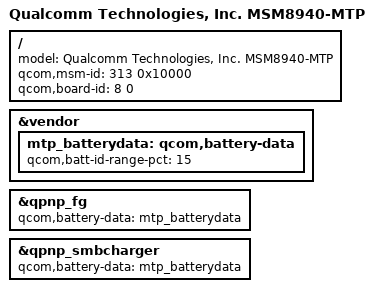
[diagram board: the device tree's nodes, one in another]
/*
 * Copyright (c) 2018, The Linux Foundation. All rights reserved.
 *
 * This program is free software; you can redistribute it and/or modify
 * it under the terms of the GNU General Public License version 2 and
 * only version 2 as published by the Free Software Foundation.
 *
 * This program is distributed in the hope that it will be useful,
 * but WITHOUT ANY WARRANTY; without even the implied warranty of
 * MERCHANTABILITY or FITNESS FOR A PARTICULAR PURPOSE.  See the
 * GNU General Public License for more details.
 */

/dts-v1/;
/plugin/;

#include <dt-bindings/gpio/gpio.h>
#include <dt-bindings/interrupt-controller/arm-gic.h>
#include "msm8940-mtp.dtsi"

/ {
	model = "Qualcomm Technologies, Inc. MSM8940-MTP";
	qcom,msm-id = <313 0x10000>;
	qcom,board-id = <8 0>;
};

&vendor {
	mtp_batterydata: qcom,battery-data {
		qcom,batt-id-range-pct = <15>;
		#include "batterydata-itech-3000mah.dtsi"
		#include "batterydata-ascent-3450mAh.dtsi"
	};
};

&qpnp_fg {
	qcom,battery-data = <&mtp_batterydata>;
};

&qpnp_smbcharger {
	qcom,battery-data = <&mtp_batterydata>;
};
